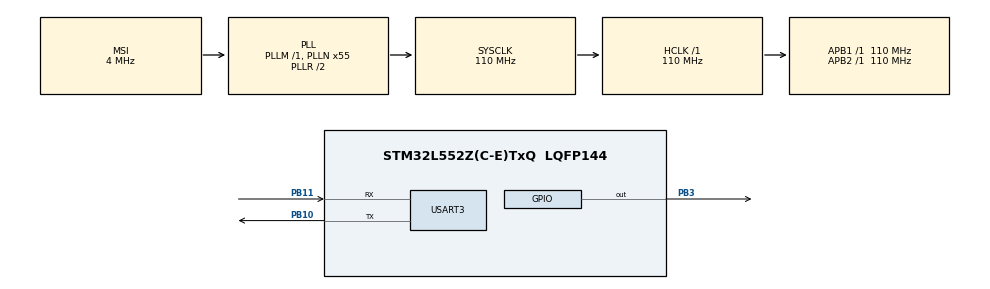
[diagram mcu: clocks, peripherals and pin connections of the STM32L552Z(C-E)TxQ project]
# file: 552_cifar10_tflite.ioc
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Mcu.Family=STM32L5
Mcu.Name=STM32L552Z(C-E)TxQ
Mcu.Package=LQFP144
NVIC.PriorityGroup=NVIC_PRIORITYGROUP_3
NVIC.TIM16_IRQn=true\:0\:0\:false\:false\:true\:true\:true
PB10.Mode=Asynchronous
PB10.Signal=USART3_TX
PB11.Mode=Asynchronous
PB11.Signal=USART3_RX
PB3\ (JTDO/TRACESWO).GPIO_PuPd=GPIO_PULLUP
PB3\ (JTDO/TRACESWO).GPIO_Speed=GPIO_SPEED_FREQ_HIGH
PB3\ (JTDO/TRACESWO).PinState=GPIO_PIN_SET
PB3\ (JTDO/TRACESWO).Signal=GPIO_Output
ProjectManager.HeapSize=0x200
ProjectManager.StackSize=0x400
ProjectManager.TargetToolchain=STM32CubeIDE
RCC.ADCFreq_Value=6000000
RCC.AHBFreq_Value=110000000
RCC.APB1Freq_Value=110000000
RCC.APB1TimFreq_Value=110000000
RCC.APB2Freq_Value=110000000
RCC.APB2TimFreq_Value=110000000
RCC.CortexFreq_Value=110000000
RCC.FLatency=FLASH_LATENCY_5
RCC.HCLKFreq_Value=110000000
RCC.HSE_VALUE=16000000
RCC.HSI48_VALUE=48000000
RCC.HSI_VALUE=16000000
RCC.LSE_VALUE=32768
RCC.MSI_VALUE=4000000
RCC.PLLM1=2
RCC.PLLM2=2
RCC.PLLN=55
RCC.PLLSAI1M=4
RCC.PLLSAI1N=48
RCC.PLLSAI1P=RCC_PLLP_DIV17
RCC.PLLSAI1Q=RCC_PLLQ_DIV4
RCC.PLLSAI1R=RCC_PLLR_DIV8
RCC.PWR_Regulator_Voltage_Scale=PWR_REGULATOR_VOLTAGE_SCALE0
RCC.RTCClockSelection=RCC_RTCCLKSOURCE_LSE
RCC.SYSCLKFreq_VALUE=110000000
RCC.SYSCLKSource=RCC_SYSCLKSOURCE_PLLCLK
RCC.USBFreq_Value=12000000
RCC.VCOOutputFreq_Value=220000000
TIM16.AutoReloadPreload=TIM_AUTORELOAD_PRELOAD_ENABLE
TIM16.Period=60000
TIM16.Prescaler=11000
USART3.VirtualMode-Asynchronous=VM_ASYNC
VP_PWR_VS_DBSignals.Mode=DisableDeadBatterySignals
VP_TIM16_VS_ClockSourceINT.Mode=Enable_Timer
board=STM32L552E-EV

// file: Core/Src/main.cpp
/* USER CODE BEGIN Header */
/**
  ******************************************************************************
  * @file           : main.c
  * @brief          : Main program body
  ******************************************************************************
  * @attention
  *
  * <h2><center>&copy; Copyright (c) 2021 STMicroelectronics.
  * All rights reserved.</center></h2>
  *
  * This software component is licensed by ST under BSD 3-Clause license,
  * the "License"; You may not use this file except in compliance with the
  * License. You may obtain a copy of the License at:
  *                        opensource.org/licenses/BSD-3-Clause
  *
  ******************************************************************************
  */
/* USER CODE END Header */
#include "main.h"

/* USER CODE BEGIN Includes */
#include "tensorflow/lite/micro/kernels/micro_ops.h"
#include "tensorflow/lite/micro/micro_error_reporter.h"
#include "tensorflow/lite/micro/micro_interpreter.h"
#include "tensorflow/lite/micro/micro_mutable_op_resolver.h"
#include "tensorflow/lite/version.h"
#include "cifar10_model.h"
#include "automobile_image.h"
/* USER CODE END Includes */

TIM_HandleTypeDef htim16;

UART_HandleTypeDef huart3;

/* USER CODE BEGIN PV */
namespace {
  tflite::ErrorReporter* error_reporter = nullptr;
  const tflite::Model* model = nullptr;
  tflite::MicroInterpreter* interpreter = nullptr;
  TfLiteTensor* model_input = nullptr;
  TfLiteTensor* model_output = nullptr;

  constexpr int kTensorArenaSize = 90000;
  __attribute__((aligned(16)))uint8_t tensor_arena[kTensorArenaSize];
}

const char* labels[] = {
    "airplane",
    "automobile",
    "bird",
    "cat",
    "deer",
    "dog",
    "frog",
    "horse",
    "ship",
    "truck"
};
/* USER CODE END PV */

void SystemClock_Config(void);
static void MX_GPIO_Init(void);
static void MX_USART3_UART_Init(void);
static void MX_TIM16_Init(void);

int main(void)
{
  /* USER CODE BEGIN 1 */
  char buf[50];  // For print
  int buf_len = 0;  // For print
  TfLiteStatus tflite_status;  // For checking TFLM function result
  uint32_t num_elements;  // Input Size
  unsigned long timestamp = 0, inference_time = 0;  // Inference time
  int max_index;
  uint8_t value = 0;
  /* USER CODE END 1 */

  /* MCU Configuration--------------------------------------------------------*/

  /* Reset of all peripherals, Initializes the Flash interface and the Systick. */
  HAL_Init();

  /* Configure the system clock */
  SystemClock_Config();

  /* Initialize all configured peripherals */
  MX_GPIO_Init();
  MX_USART3_UART_Init();
  MX_TIM16_Init();
  /* USER CODE BEGIN 2 */
  HAL_TIM_Base_Start(&htim16);

  static tflite::MicroErrorReporter micro_error_reporter;
  error_reporter = &micro_error_reporter;
  error_reporter->Report("STM32 Tensorflow Lite test");

  model = tflite::GetModel(cifar10_model_tflite);
  if(model->version() != TFLITE_SCHEMA_VERSION)
  {
	  error_reporter->Report("Model version does not match Schema");
	  while(1);
  }

  static tflite::MicroMutableOpResolver<4> micro_op_resolver;

  micro_op_resolver.AddBuiltin(
		  tflite::BuiltinOperator_CONV_2D,
		  tflite::ops::micro::Register_CONV_2D());
  micro_op_resolver.AddBuiltin(
		  tflite::BuiltinOperator_MAX_POOL_2D,
		  tflite::ops::micro::Register_MAX_POOL_2D());
  micro_op_resolver.AddBuiltin(
		  tflite::BuiltinOperator_FULLY_CONNECTED,
		  tflite::ops::micro::Register_FULLY_CONNECTED());
  micro_op_resolver.AddBuiltin(
		  tflite::BuiltinOperator_SOFTMAX,
		  tflite::ops::micro::Register_SOFTMAX());

  static tflite::MicroInterpreter static_interpreter(
		  model, micro_op_resolver, tensor_arena, kTensorArenaSize, error_reporter);
  interpreter = &static_interpreter;

  tflite_status = interpreter->AllocateTensors();
  if(tflite_status != kTfLiteOk)
  {
	  error_reporter->Report("AllocateTensors() failed");
	  buf_len = sprintf(buf, "AllocateTensors() failed\r\n");
	  HAL_UART_Transmit(&huart3, (uint8_t *)buf, buf_len, 100);
	  while(1);
  }

  model_input = interpreter->input(0);
  model_output = interpreter->output(0);

  num_elements = model_input->bytes / sizeof(uint8);
  buf_len = sprintf(buf, "\r\nNumber of input elements: %lu\r\n", num_elements);
  HAL_UART_Transmit(&huart3, (uint8_t *)buf, buf_len, 100);
  /* USER CODE END 2 */

  /* Infinite loop */
  while (1)
  {
//  	timestamp = htim16.Instance->CNT;
//
//  	if(timestamp - inference_time >= 10000){
//  	  inference_time = timestamp;
//  	  buf_len = sprintf(buf, "1 sec\r\n");
//  	  HAL_UART_Transmit(&huart3, (uint8_t *)buf, buf_len, 100);
//  	}
    for (uint32_t i = 0; i < num_elements; i++)
	{
	  model_input->data.uint8[i] = image_data[i];
	}

	timestamp = HAL_GetTick();
	tflite_status = interpreter->Invoke();
	if (tflite_status != kTfLiteOk)
	{
		error_reporter->Report("Invoke failed");
	}
	inference_time = HAL_GetTick() - timestamp;

	for(int i=0; i<10; i++){
		if(value < model_output->data.uint8[i]){
			value = model_output->data.uint8[i];
			max_index = i;
		}
	}
	buf_len = sprintf(buf, "Detected : %s (confidence : %.2f%%)\r\n", labels[max_index], (float)value/256*100);
	HAL_UART_Transmit(&huart3, (uint8_t *)buf, buf_len, 100);

    buf_len = sprintf(buf, "Duration: %lu ms \r\n\r\n", inference_time);
	HAL_UART_Transmit(&huart3, (uint8_t *)buf, buf_len, 100);
  }
}

void SystemClock_Config(void)
{
  RCC_OscInitTypeDef RCC_OscInitStruct = {0};
  RCC_ClkInitTypeDef RCC_ClkInitStruct = {0};

  /** Configure the main internal regulator output voltage
  */
  if (HAL_PWREx_ControlVoltageScaling(PWR_REGULATOR_VOLTAGE_SCALE0) != HAL_OK)
  {
    Error_Handler();
  }
  /** Initializes the RCC Oscillators according to the specified parameters
  * in the RCC_OscInitTypeDef structure.
  */
  RCC_OscInitStruct.OscillatorType = RCC_OSCILLATORTYPE_MSI;
  RCC_OscInitStruct.MSIState = RCC_MSI_ON;
  RCC_OscInitStruct.MSICalibrationValue = RCC_MSICALIBRATION_DEFAULT;
  RCC_OscInitStruct.MSIClockRange = RCC_MSIRANGE_6;
  RCC_OscInitStruct.PLL.PLLState = RCC_PLL_ON;
  RCC_OscInitStruct.PLL.PLLSource = RCC_PLLSOURCE_MSI;
  RCC_OscInitStruct.PLL.PLLM = 1;
  RCC_OscInitStruct.PLL.PLLN = 55;
  RCC_OscInitStruct.PLL.PLLP = RCC_PLLP_DIV7;
  RCC_OscInitStruct.PLL.PLLQ = RCC_PLLQ_DIV2;
  RCC_OscInitStruct.PLL.PLLR = RCC_PLLR_DIV2;
  if (HAL_RCC_OscConfig(&RCC_OscInitStruct) != HAL_OK)
  {
    Error_Handler();
  }
  /** Initializes the CPU, AHB and APB buses clocks
  */
  RCC_ClkInitStruct.ClockType = RCC_CLOCKTYPE_HCLK|RCC_CLOCKTYPE_SYSCLK
                              |RCC_CLOCKTYPE_PCLK1|RCC_CLOCKTYPE_PCLK2;
  RCC_ClkInitStruct.SYSCLKSource = RCC_SYSCLKSOURCE_PLLCLK;
  RCC_ClkInitStruct.AHBCLKDivider = RCC_SYSCLK_DIV1;
  RCC_ClkInitStruct.APB1CLKDivider = RCC_HCLK_DIV1;
  RCC_ClkInitStruct.APB2CLKDivider = RCC_HCLK_DIV1;

  if (HAL_RCC_ClockConfig(&RCC_ClkInitStruct, FLASH_LATENCY_5) != HAL_OK)
  {
    Error_Handler();
  }
}

static void MX_TIM16_Init(void)
{

  htim16.Instance = TIM16;
  htim16.Init.Prescaler = 11000;
  htim16.Init.CounterMode = TIM_COUNTERMODE_UP;
  htim16.Init.Period = 60000;
  htim16.Init.ClockDivision = TIM_CLOCKDIVISION_DIV1;
  htim16.Init.RepetitionCounter = 0;
  htim16.Init.AutoReloadPreload = TIM_AUTORELOAD_PRELOAD_ENABLE;
  if (HAL_TIM_Base_Init(&htim16) != HAL_OK)
  {
    Error_Handler();
  }

}

static void MX_USART3_UART_Init(void)
{

  huart3.Instance = USART3;
  huart3.Init.BaudRate = 115200;
  huart3.Init.WordLength = UART_WORDLENGTH_8B;
  huart3.Init.StopBits = UART_STOPBITS_1;
  huart3.Init.Parity = UART_PARITY_NONE;
  huart3.Init.Mode = UART_MODE_TX_RX;
  huart3.Init.HwFlowCtl = UART_HWCONTROL_NONE;
  huart3.Init.OverSampling = UART_OVERSAMPLING_16;
  huart3.Init.OneBitSampling = UART_ONE_BIT_SAMPLE_DISABLE;
  huart3.Init.ClockPrescaler = UART_PRESCALER_DIV1;
  huart3.AdvancedInit.AdvFeatureInit = UART_ADVFEATURE_NO_INIT;
  if (HAL_UART_Init(&huart3) != HAL_OK)
  {
    Error_Handler();
  }
  if (HAL_UARTEx_SetTxFifoThreshold(&huart3, UART_TXFIFO_THRESHOLD_1_8) != HAL_OK)
  {
    Error_Handler();
  }
  if (HAL_UARTEx_SetRxFifoThreshold(&huart3, UART_RXFIFO_THRESHOLD_1_8) != HAL_OK)
  {
    Error_Handler();
  }
  if (HAL_UARTEx_DisableFifoMode(&huart3) != HAL_OK)
  {
    Error_Handler();
  }

}

static void MX_GPIO_Init(void)
{
  GPIO_InitTypeDef GPIO_InitStruct = {0};

  /* GPIO Ports Clock Enable */
  __HAL_RCC_GPIOB_CLK_ENABLE();

  /*Configure GPIO pin Output Level */
  HAL_GPIO_WritePin(GPIOB, GPIO_PIN_3, GPIO_PIN_SET);

  /*Configure GPIO pin : PB3 */
  GPIO_InitStruct.Pin = GPIO_PIN_3;
  GPIO_InitStruct.Mode = GPIO_MODE_OUTPUT_PP;
  GPIO_InitStruct.Pull = GPIO_PULLUP;
  GPIO_InitStruct.Speed = GPIO_SPEED_FREQ_HIGH;
  HAL_GPIO_Init(GPIOB, &GPIO_InitStruct);

}

/* USER CODE BEGIN 4 */
void HAL_TIM_PeriodElapsedCallback(TIM_HandleTypeDef *htim)
{
  char buf[50];  // For print
  int buf_len = 0;  // For print
  buf_len = sprintf(buf, "timer interrupt \r\n");
  HAL_UART_Transmit(&huart3, (uint8_t *)buf, buf_len, 100);
}
/* USER CODE END 4 */

void Error_Handler(void)
{
}

/************************ (C) COPYRIGHT STMicroelectronics *****END OF FILE****/
